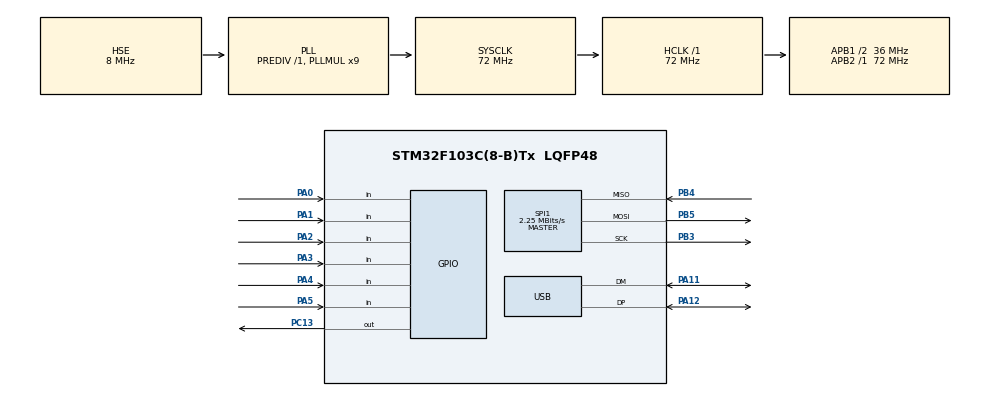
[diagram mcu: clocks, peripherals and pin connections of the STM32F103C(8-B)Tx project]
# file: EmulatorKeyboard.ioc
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Mcu.Family=STM32F1
Mcu.Name=STM32F103C(8-B)Tx
Mcu.Package=LQFP48
NVIC.PriorityGroup=NVIC_PRIORITYGROUP_4
NVIC.USB_LP_CAN1_RX0_IRQn=true\:0\:0\:false\:false\:true\:false\:true
PA0-WKUP.GPIO_PuPd=GPIO_PULLDOWN
PA0-WKUP.Signal=GPIO_Input
PA1.GPIO_PuPd=GPIO_PULLDOWN
PA1.Signal=GPIO_Input
PA11.Mode=Device
PA11.Signal=USB_DM
PA12.Mode=Device
PA12.Signal=USB_DP
PA13.Mode=Serial_Wire
PA13.Signal=SYS_JTMS-SWDIO
PA14.Mode=Serial_Wire
PA14.Signal=SYS_JTCK-SWCLK
PA2.GPIO_PuPd=GPIO_PULLDOWN
PA2.Signal=GPIO_Input
PA3.GPIO_PuPd=GPIO_PULLDOWN
PA3.Signal=GPIO_Input
PA4.GPIO_PuPd=GPIO_PULLDOWN
PA4.Signal=GPIO_Input
PA5.GPIO_PuPd=GPIO_PULLDOWN
PA5.Signal=GPIO_Input
PB3.Mode=Full_Duplex_Master
PB3.Signal=SPI1_SCK
PB4.Mode=Full_Duplex_Master
PB4.Signal=SPI1_MISO
PB5.Mode=Full_Duplex_Master
PB5.Signal=SPI1_MOSI
PC13-TAMPER-RTC.GPIO_PuPd=GPIO_PULLDOWN
PC13-TAMPER-RTC.PinState=GPIO_PIN_SET
PC13-TAMPER-RTC.Signal=GPIO_Output
PD0-OSC_IN.Mode=HSE-External-Oscillator
PD0-OSC_IN.Signal=RCC_OSC_IN
PD1-OSC_OUT.Mode=HSE-External-Oscillator
PD1-OSC_OUT.Signal=RCC_OSC_OUT
ProjectManager.HeapSize=0x200
ProjectManager.StackSize=0x400
ProjectManager.TargetToolchain=MDK-ARM V5.32
RCC.AHBFreq_Value=72000000
RCC.APB1CLKDivider=RCC_HCLK_DIV2
RCC.APB1Freq_Value=36000000
RCC.APB1TimFreq_Value=72000000
RCC.APB2Freq_Value=72000000
RCC.APB2TimFreq_Value=72000000
RCC.HCLKFreq_Value=72000000
RCC.PLLMUL=RCC_PLL_MUL9
RCC.SYSCLKFreq_VALUE=72000000
RCC.SYSCLKSource=RCC_SYSCLKSOURCE_PLLCLK
RCC.USBFreq_Value=48000000
RCC.USBPrescaler=RCC_USBCLKSOURCE_PLL_DIV1_5
SPI1.BaudRatePrescaler=SPI_BAUDRATEPRESCALER_32
SPI1.CalculateBaudRate=2.25 MBits/s
SPI1.Direction=SPI_DIRECTION_2LINES
SPI1.Mode=SPI_MODE_MASTER
SPI1.VirtualType=VM_MASTER
USB_DEVICE.CLASS_NAME_FS=HID
USB_DEVICE.PRODUCT_STRING_HID_FS=EmulatorKeyboard
USB_DEVICE.VirtualMode=Hid
USB_DEVICE.VirtualModeFS=Hid_FS
VP_USB_DEVICE_VS_USB_DEVICE_HID_FS.Mode=HID_FS
board=custom

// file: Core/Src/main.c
/* USER CODE BEGIN Header */
/**
  ******************************************************************************
  * @file           : main.c
  * @brief          : Main program body
  ******************************************************************************
  * @attention
  *
  * Copyright (c) 2022 STMicroelectronics.
  * All rights reserved.
  *
  * This software is licensed under terms that can be found in the LICENSE file
  * in the root directory of this software component.
  * If no LICENSE file comes with this software, it is provided AS-IS.
  *
  ******************************************************************************
  */
/* USER CODE END Header */
#include "main.h"
#include "usb_device.h"

/* USER CODE BEGIN Includes */
//#include "usbd_hid.h"
#include "keys.h"

/* USER CODE END Includes */

/* USER CODE BEGIN PD */
#define READ_PIN_A0 HAL_GPIO_ReadPin(GPIOA,GPIO_PIN_0)
#define READ_PIN_A1 HAL_GPIO_ReadPin(GPIOA,GPIO_PIN_1)
/* USER CODE END PD */

SPI_HandleTypeDef hspi1;

void SystemClock_Config(void);
static void MX_GPIO_Init(void);
static void MX_SPI1_Init(void);

int main(void)
{

  /* MCU Configuration--------------------------------------------------------*/

  /* Reset of all peripherals, Initializes the Flash interface and the Systick. */
  HAL_Init();

  /* Configure the system clock */
  SystemClock_Config();

  /* Initialize all configured peripherals */
  MX_GPIO_Init();
  MX_USB_DEVICE_Init();
  MX_SPI1_Init();

  /* Infinite loop */
  while (1)
  {

    /* USER CODE BEGIN 3 */

		if(READ_PIN_A0){
			HAL_GPIO_WritePin(GPIOC, GPIO_PIN_13, GPIO_PIN_RESET);

			grup_1_up ();
		}

		if(READ_PIN_A1){
			HAL_GPIO_WritePin(GPIOC, GPIO_PIN_13, GPIO_PIN_SET);

			grup_1_down ();
		}

  }
  /* USER CODE END 3 */
}

void SystemClock_Config(void)
{
  RCC_OscInitTypeDef RCC_OscInitStruct = {0};
  RCC_ClkInitTypeDef RCC_ClkInitStruct = {0};
  RCC_PeriphCLKInitTypeDef PeriphClkInit = {0};

  /** Initializes the RCC Oscillators according to the specified parameters
  * in the RCC_OscInitTypeDef structure.
  */
  RCC_OscInitStruct.OscillatorType = RCC_OSCILLATORTYPE_HSE;
  RCC_OscInitStruct.HSEState = RCC_HSE_ON;
  RCC_OscInitStruct.HSEPredivValue = RCC_HSE_PREDIV_DIV1;
  RCC_OscInitStruct.HSIState = RCC_HSI_ON;
  RCC_OscInitStruct.PLL.PLLState = RCC_PLL_ON;
  RCC_OscInitStruct.PLL.PLLSource = RCC_PLLSOURCE_HSE;
  RCC_OscInitStruct.PLL.PLLMUL = RCC_PLL_MUL9;
  if (HAL_RCC_OscConfig(&RCC_OscInitStruct) != HAL_OK)
  {
    Error_Handler();
  }
  /** Initializes the CPU, AHB and APB buses clocks
  */
  RCC_ClkInitStruct.ClockType = RCC_CLOCKTYPE_HCLK|RCC_CLOCKTYPE_SYSCLK
                              |RCC_CLOCKTYPE_PCLK1|RCC_CLOCKTYPE_PCLK2;
  RCC_ClkInitStruct.SYSCLKSource = RCC_SYSCLKSOURCE_PLLCLK;
  RCC_ClkInitStruct.AHBCLKDivider = RCC_SYSCLK_DIV1;
  RCC_ClkInitStruct.APB1CLKDivider = RCC_HCLK_DIV2;
  RCC_ClkInitStruct.APB2CLKDivider = RCC_HCLK_DIV1;

  if (HAL_RCC_ClockConfig(&RCC_ClkInitStruct, FLASH_LATENCY_2) != HAL_OK)
  {
    Error_Handler();
  }
  PeriphClkInit.PeriphClockSelection = RCC_PERIPHCLK_USB;
  PeriphClkInit.UsbClockSelection = RCC_USBCLKSOURCE_PLL_DIV1_5;
  if (HAL_RCCEx_PeriphCLKConfig(&PeriphClkInit) != HAL_OK)
  {
    Error_Handler();
  }
}

static void MX_SPI1_Init(void)
{

  /* SPI1 parameter configuration*/
  hspi1.Instance = SPI1;
  hspi1.Init.Mode = SPI_MODE_MASTER;
  hspi1.Init.Direction = SPI_DIRECTION_2LINES;
  hspi1.Init.DataSize = SPI_DATASIZE_8BIT;
  hspi1.Init.CLKPolarity = SPI_POLARITY_LOW;
  hspi1.Init.CLKPhase = SPI_PHASE_1EDGE;
  hspi1.Init.NSS = SPI_NSS_SOFT;
  hspi1.Init.BaudRatePrescaler = SPI_BAUDRATEPRESCALER_32;
  hspi1.Init.FirstBit = SPI_FIRSTBIT_MSB;
  hspi1.Init.TIMode = SPI_TIMODE_DISABLE;
  hspi1.Init.CRCCalculation = SPI_CRCCALCULATION_DISABLE;
  hspi1.Init.CRCPolynomial = 10;
  if (HAL_SPI_Init(&hspi1) != HAL_OK)
  {
    Error_Handler();
  }

}

static void MX_GPIO_Init(void)
{
  GPIO_InitTypeDef GPIO_InitStruct = {0};

  /* GPIO Ports Clock Enable */
  __HAL_RCC_GPIOC_CLK_ENABLE();
  __HAL_RCC_GPIOD_CLK_ENABLE();
  __HAL_RCC_GPIOA_CLK_ENABLE();
  __HAL_RCC_GPIOB_CLK_ENABLE();

  /*Configure GPIO pin Output Level */
  HAL_GPIO_WritePin(GPIOC, GPIO_PIN_13, GPIO_PIN_SET);

  /*Configure GPIO pin : PC13 */
  GPIO_InitStruct.Pin = GPIO_PIN_13;
  GPIO_InitStruct.Mode = GPIO_MODE_OUTPUT_PP;
  GPIO_InitStruct.Pull = GPIO_PULLDOWN;
  GPIO_InitStruct.Speed = GPIO_SPEED_FREQ_LOW;
  HAL_GPIO_Init(GPIOC, &GPIO_InitStruct);

  /*Configure GPIO pins : PA0 PA1 PA2 PA3
                           PA4 PA5 */
  GPIO_InitStruct.Pin = GPIO_PIN_0|GPIO_PIN_1|GPIO_PIN_2|GPIO_PIN_3
                          |GPIO_PIN_4|GPIO_PIN_5;
  GPIO_InitStruct.Mode = GPIO_MODE_INPUT;
  GPIO_InitStruct.Pull = GPIO_PULLDOWN;
  HAL_GPIO_Init(GPIOA, &GPIO_InitStruct);

}

void Error_Handler(void)
{
  __disable_irq();
  while (1)
  {
  }
}
